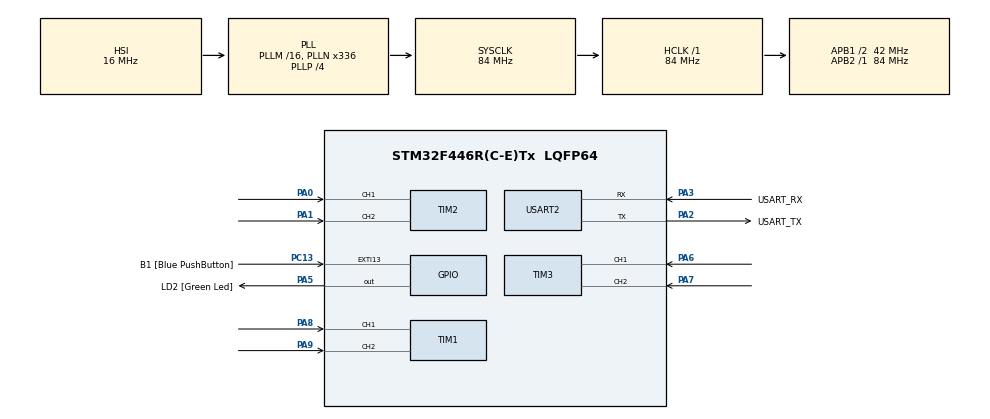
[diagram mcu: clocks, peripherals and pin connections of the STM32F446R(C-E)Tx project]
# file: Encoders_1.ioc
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Mcu.Family=STM32F4
Mcu.Name=STM32F446R(C-E)Tx
Mcu.Package=LQFP64
NVIC.PriorityGroup=NVIC_PRIORITYGROUP_0
PA0-WKUP.GPIO_PuPd=GPIO_PULLUP
PA0-WKUP.Signal=S_TIM2_CH1_ETR
PA1.GPIO_PuPd=GPIO_PULLUP
PA1.Signal=S_TIM2_CH2
PA13.GPIO_Label=TMS
PA13.Mode=Serial_Wire
PA13.Signal=SYS_JTMS-SWDIO
PA14.GPIO_Label=TCK
PA14.Mode=Serial_Wire
PA14.Signal=SYS_JTCK-SWCLK
PA2.GPIO_Label=USART_TX
PA2.Mode=Asynchronous
PA2.Signal=USART2_TX
PA3.GPIO_Label=USART_RX
PA3.Mode=Asynchronous
PA3.Signal=USART2_RX
PA5.GPIO_Label=LD2 [Green Led]
PA5.Signal=GPIO_Output
PA6.GPIO_PuPd=GPIO_PULLUP
PA6.Signal=S_TIM3_CH1
PA7.GPIO_PuPd=GPIO_PULLUP
PA7.Signal=S_TIM3_CH2
PA8.GPIO_PuPd=GPIO_PULLUP
PA8.Signal=S_TIM1_CH1
PA9.GPIO_PuPd=GPIO_PULLUP
PA9.Signal=S_TIM1_CH2
PB3.GPIO_Label=SWO
PB3.Signal=SYS_JTDO-SWO
PC13.GPIO_Label=B1 [Blue PushButton]
PC13.GPIO_ModeDefaultEXTI=GPIO_MODE_IT_FALLING
PC13.Signal=GPXTI13
PC14-OSC32_IN.Mode=LSE-External-Oscillator
PC14-OSC32_IN.Signal=RCC_OSC32_IN
PC15-OSC32_OUT.Mode=LSE-External-Oscillator
PC15-OSC32_OUT.Signal=RCC_OSC32_OUT
PH0-OSC_IN.Mode=HSE-External-Oscillator
PH0-OSC_IN.Signal=RCC_OSC_IN
PH1-OSC_OUT.Mode=HSE-External-Oscillator
PH1-OSC_OUT.Signal=RCC_OSC_OUT
ProjectManager.HeapSize=0x200
ProjectManager.StackSize=0x400
ProjectManager.TargetToolchain=STM32CubeIDE
RCC.48MHZClocksFreq_Value=84000000
RCC.AHBFreq_Value=84000000
RCC.APB1CLKDivider=RCC_HCLK_DIV2
RCC.APB1Freq_Value=42000000
RCC.APB1TimFreq_Value=84000000
RCC.APB2Freq_Value=84000000
RCC.APB2TimFreq_Value=84000000
RCC.CortexFreq_Value=84000000
RCC.FLatency-AdvancedSettings=FLASH_LATENCY_2
RCC.HCLKFreq_Value=84000000
RCC.HSE_VALUE=8000000
RCC.HSI_VALUE=16000000
RCC.PLLN=336
RCC.PLLP=RCC_PLLP_DIV4
RCC.SYSCLKFreq_VALUE=84000000
RCC.SYSCLKSource=RCC_SYSCLKSOURCE_PLLCLK
RCC.USBFreq_Value=168000000
RCC.VCOOutputFreq_Value=336000000
SH.S_TIM1_CH1.0=TIM1_CH1,Encoder_Interface
SH.S_TIM1_CH2.0=TIM1_CH2,Encoder_Interface
SH.S_TIM2_CH1_ETR.0=TIM2_CH1,Encoder_Interface
SH.S_TIM2_CH2.0=TIM2_CH2,Encoder_Interface
SH.S_TIM3_CH1.0=TIM3_CH1,Encoder_Interface
SH.S_TIM3_CH2.0=TIM3_CH2,Encoder_Interface
TIM1.EncoderMode=TIM_ENCODERMODE_TI1
TIM1.IC1Filter=5
TIM1.IC2Filter=5
TIM2.EncoderMode=TIM_ENCODERMODE_TI1
TIM2.IC1Filter=5
TIM2.IC2Filter=5
TIM3.EncoderMode=TIM_ENCODERMODE_TI1
TIM3.IC1Filter=5
TIM3.IC2Filter=5
USART2.VirtualMode=VM_ASYNC
board=NUCLEO-F446RE

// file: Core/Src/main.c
/* USER CODE BEGIN Header */
/**
 ******************************************************************************
 * @file           : main.c
 * @brief          : Main program body
 ******************************************************************************
 * @attention
 *
 * Copyright (c) 2025 STMicroelectronics.
 * All rights reserved.
 *
 * This software is licensed under terms that can be found in the LICENSE file
 * in the root directory of this software component.
 * If no LICENSE file comes with this software, it is provided AS-IS.
 *
 ******************************************************************************
 */
/* USER CODE END Header */
#include "main.h"

/* USER CODE BEGIN Includes */
#include <stdio.h>
/* USER CODE END Includes */

/* USER CODE BEGIN PD */
//#define CW_MIN 0
//#define CW_MAX 32767
//#define CCW_MIN 32768
//#define CCW_MAX 65535
/* USER CODE END PD */

TIM_HandleTypeDef htim1;
TIM_HandleTypeDef htim2;
TIM_HandleTypeDef htim3;

UART_HandleTypeDef huart2;

void SystemClock_Config(void);
static void MX_GPIO_Init(void);
static void MX_USART2_UART_Init(void);
static void MX_TIM1_Init(void);
static void MX_TIM2_Init(void);
static void MX_TIM3_Init(void);

int main(void)
{

  /* MCU Configuration--------------------------------------------------------*/

  /* Reset of all peripherals, Initializes the Flash interface and the Systick. */
  HAL_Init();

  /* Configure the system clock */
  SystemClock_Config();

  /* Initialize all configured peripherals */
  MX_GPIO_Init();
  MX_USART2_UART_Init();
  MX_TIM1_Init();
  MX_TIM2_Init();
  MX_TIM3_Init();
  /* USER CODE BEGIN 2 */
	HAL_TIM_Encoder_Start(&htim1, TIM_CHANNEL_ALL);
	HAL_TIM_Encoder_Start(&htim2, TIM_CHANNEL_ALL);
	HAL_TIM_Encoder_Start(&htim3, TIM_CHANNEL_ALL);

  /* USER CODE END 2 */

  /* Infinite loop */
	while (1) {

    /* USER CODE BEGIN 3 */
//		printf("Encoder position: %u %u %u\r\n", __HAL_TIM_GET_COUNTER(&htim1), __HAL_TIM_GET_COUNTER(&htim2), __HAL_TIM_GET_COUNTER(&htim3));
		uint16_t raw_counter1 = __HAL_TIM_GET_COUNTER(&htim1);
		  uint32_t raw_counter2 = __HAL_TIM_GET_COUNTER(&htim2);
		  uint16_t raw_counter3 = __HAL_TIM_GET_COUNTER(&htim3);

		  // Convert to signed values
		  int16_t signed_counter1 = (raw_counter1 < 32768) ? (int16_t)raw_counter1 : (int16_t)(raw_counter1 - 65536);
		  int32_t signed_counter2 = (raw_counter2 < 2147483648) ? (int32_t)raw_counter2 : (int32_t)(raw_counter2 - 4294967296);
		  int16_t signed_counter3 = (raw_counter3 < 32768) ? (int16_t)raw_counter3 : (int16_t)(raw_counter3 - 65536);

		  printf("Encoder position: %d %d %d\r\n", signed_counter1, signed_counter2, signed_counter3);

	}
  /* USER CODE END 3 */
}

void SystemClock_Config(void)
{
  RCC_OscInitTypeDef RCC_OscInitStruct = {0};
  RCC_ClkInitTypeDef RCC_ClkInitStruct = {0};

  /** Configure the main internal regulator output voltage
  */
  __HAL_RCC_PWR_CLK_ENABLE();
  __HAL_PWR_VOLTAGESCALING_CONFIG(PWR_REGULATOR_VOLTAGE_SCALE3);

  /** Initializes the RCC Oscillators according to the specified parameters
  * in the RCC_OscInitTypeDef structure.
  */
  RCC_OscInitStruct.OscillatorType = RCC_OSCILLATORTYPE_HSI;
  RCC_OscInitStruct.HSIState = RCC_HSI_ON;
  RCC_OscInitStruct.HSICalibrationValue = RCC_HSICALIBRATION_DEFAULT;
  RCC_OscInitStruct.PLL.PLLState = RCC_PLL_ON;
  RCC_OscInitStruct.PLL.PLLSource = RCC_PLLSOURCE_HSI;
  RCC_OscInitStruct.PLL.PLLM = 16;
  RCC_OscInitStruct.PLL.PLLN = 336;
  RCC_OscInitStruct.PLL.PLLP = RCC_PLLP_DIV4;
  RCC_OscInitStruct.PLL.PLLQ = 2;
  RCC_OscInitStruct.PLL.PLLR = 2;
  if (HAL_RCC_OscConfig(&RCC_OscInitStruct) != HAL_OK)
  {
    Error_Handler();
  }

  /** Initializes the CPU, AHB and APB buses clocks
  */
  RCC_ClkInitStruct.ClockType = RCC_CLOCKTYPE_HCLK|RCC_CLOCKTYPE_SYSCLK
                              |RCC_CLOCKTYPE_PCLK1|RCC_CLOCKTYPE_PCLK2;
  RCC_ClkInitStruct.SYSCLKSource = RCC_SYSCLKSOURCE_PLLCLK;
  RCC_ClkInitStruct.AHBCLKDivider = RCC_SYSCLK_DIV1;
  RCC_ClkInitStruct.APB1CLKDivider = RCC_HCLK_DIV2;
  RCC_ClkInitStruct.APB2CLKDivider = RCC_HCLK_DIV1;

  if (HAL_RCC_ClockConfig(&RCC_ClkInitStruct, FLASH_LATENCY_2) != HAL_OK)
  {
    Error_Handler();
  }
}

static void MX_TIM1_Init(void)
{

  TIM_Encoder_InitTypeDef sConfig = {0};
  TIM_MasterConfigTypeDef sMasterConfig = {0};

  htim1.Instance = TIM1;
  htim1.Init.Prescaler = 0;
  htim1.Init.CounterMode = TIM_COUNTERMODE_UP;
  htim1.Init.Period = 65535;
  htim1.Init.ClockDivision = TIM_CLOCKDIVISION_DIV1;
  htim1.Init.RepetitionCounter = 0;
  htim1.Init.AutoReloadPreload = TIM_AUTORELOAD_PRELOAD_DISABLE;
  sConfig.EncoderMode = TIM_ENCODERMODE_TI1;
  sConfig.IC1Polarity = TIM_ICPOLARITY_RISING;
  sConfig.IC1Selection = TIM_ICSELECTION_DIRECTTI;
  sConfig.IC1Prescaler = TIM_ICPSC_DIV1;
  sConfig.IC1Filter = 5;
  sConfig.IC2Polarity = TIM_ICPOLARITY_RISING;
  sConfig.IC2Selection = TIM_ICSELECTION_DIRECTTI;
  sConfig.IC2Prescaler = TIM_ICPSC_DIV1;
  sConfig.IC2Filter = 5;
  if (HAL_TIM_Encoder_Init(&htim1, &sConfig) != HAL_OK)
  {
    Error_Handler();
  }
  sMasterConfig.MasterOutputTrigger = TIM_TRGO_RESET;
  sMasterConfig.MasterSlaveMode = TIM_MASTERSLAVEMODE_DISABLE;
  if (HAL_TIMEx_MasterConfigSynchronization(&htim1, &sMasterConfig) != HAL_OK)
  {
    Error_Handler();
  }

}

static void MX_TIM2_Init(void)
{

  TIM_Encoder_InitTypeDef sConfig = {0};
  TIM_MasterConfigTypeDef sMasterConfig = {0};

  htim2.Instance = TIM2;
  htim2.Init.Prescaler = 0;
  htim2.Init.CounterMode = TIM_COUNTERMODE_UP;
  htim2.Init.Period = 4294967295;
  htim2.Init.ClockDivision = TIM_CLOCKDIVISION_DIV1;
  htim2.Init.AutoReloadPreload = TIM_AUTORELOAD_PRELOAD_DISABLE;
  sConfig.EncoderMode = TIM_ENCODERMODE_TI1;
  sConfig.IC1Polarity = TIM_ICPOLARITY_RISING;
  sConfig.IC1Selection = TIM_ICSELECTION_DIRECTTI;
  sConfig.IC1Prescaler = TIM_ICPSC_DIV1;
  sConfig.IC1Filter = 5;
  sConfig.IC2Polarity = TIM_ICPOLARITY_RISING;
  sConfig.IC2Selection = TIM_ICSELECTION_DIRECTTI;
  sConfig.IC2Prescaler = TIM_ICPSC_DIV1;
  sConfig.IC2Filter = 5;
  if (HAL_TIM_Encoder_Init(&htim2, &sConfig) != HAL_OK)
  {
    Error_Handler();
  }
  sMasterConfig.MasterOutputTrigger = TIM_TRGO_RESET;
  sMasterConfig.MasterSlaveMode = TIM_MASTERSLAVEMODE_DISABLE;
  if (HAL_TIMEx_MasterConfigSynchronization(&htim2, &sMasterConfig) != HAL_OK)
  {
    Error_Handler();
  }

}

static void MX_TIM3_Init(void)
{

  TIM_Encoder_InitTypeDef sConfig = {0};
  TIM_MasterConfigTypeDef sMasterConfig = {0};

  htim3.Instance = TIM3;
  htim3.Init.Prescaler = 0;
  htim3.Init.CounterMode = TIM_COUNTERMODE_UP;
  htim3.Init.Period = 65535;
  htim3.Init.ClockDivision = TIM_CLOCKDIVISION_DIV1;
  htim3.Init.AutoReloadPreload = TIM_AUTORELOAD_PRELOAD_DISABLE;
  sConfig.EncoderMode = TIM_ENCODERMODE_TI1;
  sConfig.IC1Polarity = TIM_ICPOLARITY_RISING;
  sConfig.IC1Selection = TIM_ICSELECTION_DIRECTTI;
  sConfig.IC1Prescaler = TIM_ICPSC_DIV1;
  sConfig.IC1Filter = 5;
  sConfig.IC2Polarity = TIM_ICPOLARITY_RISING;
  sConfig.IC2Selection = TIM_ICSELECTION_DIRECTTI;
  sConfig.IC2Prescaler = TIM_ICPSC_DIV1;
  sConfig.IC2Filter = 5;
  if (HAL_TIM_Encoder_Init(&htim3, &sConfig) != HAL_OK)
  {
    Error_Handler();
  }
  sMasterConfig.MasterOutputTrigger = TIM_TRGO_RESET;
  sMasterConfig.MasterSlaveMode = TIM_MASTERSLAVEMODE_DISABLE;
  if (HAL_TIMEx_MasterConfigSynchronization(&htim3, &sMasterConfig) != HAL_OK)
  {
    Error_Handler();
  }

}

static void MX_USART2_UART_Init(void)
{

  huart2.Instance = USART2;
  huart2.Init.BaudRate = 115200;
  huart2.Init.WordLength = UART_WORDLENGTH_8B;
  huart2.Init.StopBits = UART_STOPBITS_1;
  huart2.Init.Parity = UART_PARITY_NONE;
  huart2.Init.Mode = UART_MODE_TX_RX;
  huart2.Init.HwFlowCtl = UART_HWCONTROL_NONE;
  huart2.Init.OverSampling = UART_OVERSAMPLING_16;
  if (HAL_UART_Init(&huart2) != HAL_OK)
  {
    Error_Handler();
  }

}

static void MX_GPIO_Init(void)
{
  GPIO_InitTypeDef GPIO_InitStruct = {0};

  /* GPIO Ports Clock Enable */
  __HAL_RCC_GPIOC_CLK_ENABLE();
  __HAL_RCC_GPIOH_CLK_ENABLE();
  __HAL_RCC_GPIOA_CLK_ENABLE();
  __HAL_RCC_GPIOB_CLK_ENABLE();

  /*Configure GPIO pin Output Level */
  HAL_GPIO_WritePin(LD2_GPIO_Port, LD2_Pin, GPIO_PIN_RESET);

  /*Configure GPIO pin : B1_Pin */
  GPIO_InitStruct.Pin = B1_Pin;
  GPIO_InitStruct.Mode = GPIO_MODE_IT_FALLING;
  GPIO_InitStruct.Pull = GPIO_NOPULL;
  HAL_GPIO_Init(B1_GPIO_Port, &GPIO_InitStruct);

  /*Configure GPIO pin : LD2_Pin */
  GPIO_InitStruct.Pin = LD2_Pin;
  GPIO_InitStruct.Mode = GPIO_MODE_OUTPUT_PP;
  GPIO_InitStruct.Pull = GPIO_NOPULL;
  GPIO_InitStruct.Speed = GPIO_SPEED_FREQ_LOW;
  HAL_GPIO_Init(LD2_GPIO_Port, &GPIO_InitStruct);

}

/* USER CODE BEGIN 4 */
int _write(int file, char *ptr, int len) {
	HAL_UART_Transmit(&huart2, (uint8_t*) ptr, len, HAL_MAX_DELAY);
	return len;
}
/* USER CODE END 4 */

void Error_Handler(void)
{
	__disable_irq();
	while (1) {
	}
}
